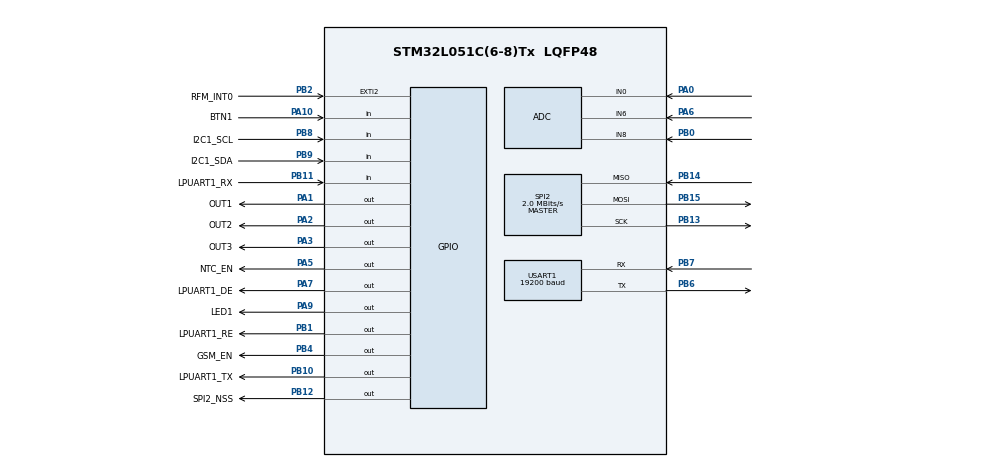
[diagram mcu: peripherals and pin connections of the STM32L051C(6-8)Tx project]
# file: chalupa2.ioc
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ADC.EOCSelection=ADC_EOC_SEQ_CONV
ADC.Overrun=ADC_OVR_DATA_OVERWRITTEN
ADC.OversamplingMode=ENABLE
ADC.Ratio=ADC_OVERSAMPLING_RATIO_16
ADC.RightBitShift=ADC_RIGHTBITSHIFT_4
ADC.SamplingTime=ADC_SAMPLETIME_160CYCLES_5
IWDG.Prescaler=IWDG_PRESCALER_64
Mcu.Family=STM32L0
Mcu.Name=STM32L051C(6-8)Tx
Mcu.Package=LQFP48
NVIC.EXTI2_3_IRQn=true\:0\:0\:false\:false\:true\:true\:true\:true
PA0.Mode=IN0
PA0.Signal=ADC_IN0
PA1.GPIO_Label=OUT1
PA1.Signal=GPIO_Output
PA10.GPIO_Label=BTN1
PA10.GPIO_PuPd=GPIO_PULLUP
PA10.Signal=GPIO_Input
PA13.Mode=Serial_Wire
PA13.Signal=SYS_SWDIO
PA14.Mode=Serial_Wire
PA14.Signal=SYS_SWCLK
PA2.GPIO_Label=OUT2
PA2.Signal=GPIO_Output
PA3.GPIO_Label=OUT3
PA3.Signal=GPIO_Output
PA5.GPIO_Label=NTC_EN
PA5.Signal=GPIO_Output
PA6.Mode=IN6
PA6.Signal=ADC_IN6
PA7.GPIO_Label=LPUART1_DE
PA7.Signal=GPIO_Output
PA9.GPIO_Label=LED1
PA9.Signal=GPIO_Output
PB0.Mode=IN8
PB0.Signal=ADC_IN8
PB1.GPIO_Label=LPUART1_RE
PB1.PinState=GPIO_PIN_SET
PB1.Signal=GPIO_Output
PB10.GPIO_Label=LPUART1_TX
PB10.Signal=GPIO_Output
PB11.GPIO_Label=LPUART1_RX
PB11.GPIO_PuPd=GPIO_PULLUP
PB11.Signal=GPIO_Input
PB12.GPIO_Label=SPI2_NSS
PB12.GPIO_Speed=GPIO_SPEED_FREQ_VERY_HIGH
PB12.PinState=GPIO_PIN_SET
PB12.Signal=GPIO_Output
PB13.GPIO_PuPd=GPIO_PULLDOWN
PB13.Mode=Full_Duplex_Master
PB13.Signal=SPI2_SCK
PB14.GPIO_PuPd=GPIO_PULLDOWN
PB14.Mode=Full_Duplex_Master
PB14.Signal=SPI2_MISO
PB15.GPIO_PuPd=GPIO_PULLDOWN
PB15.Mode=Full_Duplex_Master
PB15.Signal=SPI2_MOSI
PB2.GPIO_Label=RFM_INT0
PB2.GPIO_ModeDefaultEXTI=GPIO_MODE_IT_FALLING
PB2.GPIO_PuPd=GPIO_PULLUP
PB2.Signal=GPXTI2
PB4.GPIO_Label=GSM_EN
PB4.Signal=GPIO_Output
PB6.Mode=Asynchronous
PB6.Signal=USART1_TX
PB7.GPIO_PuPd=GPIO_PULLDOWN
PB7.Mode=Asynchronous
PB7.Signal=USART1_RX
PB8.GPIO_Label=I2C1_SCL
PB8.Signal=GPIO_Input
PB9.GPIO_Label=I2C1_SDA
PB9.Signal=GPIO_Input
PH0-OSC_IN.Mode=HSE-External-Oscillator
PH0-OSC_IN.Signal=RCC_OSC_IN
PH1-OSC_OUT.Mode=HSE-External-Oscillator
PH1-OSC_OUT.Signal=RCC_OSC_OUT
ProjectManager.HeapSize=0x0
ProjectManager.StackSize=0x400
ProjectManager.TargetToolchain=STM32CubeIDE
RCC.AHBFreq_Value=8000000
RCC.APB1Freq_Value=8000000
RCC.APB1TimFreq_Value=8000000
RCC.APB2Freq_Value=8000000
RCC.APB2TimFreq_Value=8000000
RCC.HCLKFreq_Value=8000000
RCC.HSE_VALUE=8000000
RCC.HSI16_VALUE=16000000
RCC.HSI_VALUE=16000000
RCC.LSE_VALUE=32768
RCC.MSI_VALUE=2097000
RCC.PWR_Regulator_Voltage_Scale=PWR_REGULATOR_VOLTAGE_SCALE2
RCC.SYSCLKFreq_VALUE=8000000
RCC.SYSCLKSource=RCC_SYSCLKSOURCE_HSE
RCC.VCOOutputFreq_Value=48000000
RCC.VDD_VALUE=3
SPI2.BaudRatePrescaler=SPI_BAUDRATEPRESCALER_4
SPI2.CalculateBaudRate=2.0 MBits/s
SPI2.DataSize=SPI_DATASIZE_16BIT
SPI2.Direction=SPI_DIRECTION_2LINES
SPI2.Mode=SPI_MODE_MASTER
SPI2.VirtualType=VM_MASTER
USART1.BaudRate=19200
USART1.VirtualMode-Asynchronous=VM_ASYNC
VP_IWDG_VS_IWDG.Mode=IWDG_Activate
board=custom

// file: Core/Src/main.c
/* USER CODE BEGIN Header */
/**
  ******************************************************************************
  * @file           : main.c
  * @brief          : Main program body
  ******************************************************************************
  * @attention
  *
  * Copyright (c) 2023 STMicroelectronics.
  * All rights reserved.
  *
  * This software is licensed under terms that can be found in the LICENSE file
  * in the root directory of this software component.
  * If no LICENSE file comes with this software, it is provided AS-IS.
  *
  ******************************************************************************
  */
/* USER CODE END Header */
#include "main.h"

void SystemClock_Config(void);
static void MX_GPIO_Init(void);
static void MX_ADC_Init(void);
static void MX_USART1_UART_Init(void);
static void MX_SPI2_Init(void);
static void MX_IWDG_Init(void);
/* USER CODE BEGIN PFP */

extern void main2(void);

/* USER CODE END PFP */

int main(void)
{

  /* MCU Configuration--------------------------------------------------------*/

  /* Reset of all peripherals, Initializes the Flash interface and the Systick. */
  LL_APB2_GRP1_EnableClock(LL_APB2_GRP1_PERIPH_SYSCFG);
  LL_APB1_GRP1_EnableClock(LL_APB1_GRP1_PERIPH_PWR);

  /* SysTick_IRQn interrupt configuration */
  NVIC_SetPriority(SysTick_IRQn, 3);

  /* Configure the system clock */
  SystemClock_Config();

  /* Initialize all configured peripherals */
  MX_GPIO_Init();
  MX_ADC_Init();
  MX_USART1_UART_Init();
  MX_SPI2_Init();
  MX_IWDG_Init();
  /* USER CODE BEGIN 2 */

  main2();

  /* USER CODE END 2 */

  /* Infinite loop */
  while (1)
  {

  }
}

void SystemClock_Config(void)
{
  LL_FLASH_SetLatency(LL_FLASH_LATENCY_0);
  while(LL_FLASH_GetLatency()!= LL_FLASH_LATENCY_0)
  {
  }
  LL_PWR_SetRegulVoltageScaling(LL_PWR_REGU_VOLTAGE_SCALE2);
  LL_RCC_HSE_Enable();

   /* Wait till HSE is ready */
  while(LL_RCC_HSE_IsReady() != 1)
  {

  }
  LL_RCC_LSI_Enable();

   /* Wait till LSI is ready */
  while(LL_RCC_LSI_IsReady() != 1)
  {

  }
  LL_RCC_SetAHBPrescaler(LL_RCC_SYSCLK_DIV_1);
  LL_RCC_SetAPB1Prescaler(LL_RCC_APB1_DIV_1);
  LL_RCC_SetAPB2Prescaler(LL_RCC_APB2_DIV_1);
  LL_RCC_SetSysClkSource(LL_RCC_SYS_CLKSOURCE_HSE);

   /* Wait till System clock is ready */
  while(LL_RCC_GetSysClkSource() != LL_RCC_SYS_CLKSOURCE_STATUS_HSE)
  {

  }

  LL_Init1msTick(8000000);

  LL_SetSystemCoreClock(8000000);
  LL_RCC_SetUSARTClockSource(LL_RCC_USART1_CLKSOURCE_PCLK2);
}

static void MX_ADC_Init(void)
{

  LL_ADC_REG_InitTypeDef ADC_REG_InitStruct = {0};
  LL_ADC_InitTypeDef ADC_InitStruct = {0};

  LL_GPIO_InitTypeDef GPIO_InitStruct = {0};

  /* Peripheral clock enable */
  LL_APB2_GRP1_EnableClock(LL_APB2_GRP1_PERIPH_ADC1);

  LL_IOP_GRP1_EnableClock(LL_IOP_GRP1_PERIPH_GPIOA);
  LL_IOP_GRP1_EnableClock(LL_IOP_GRP1_PERIPH_GPIOB);
  /**ADC GPIO Configuration
  PA0   ------> ADC_IN0
  PA6   ------> ADC_IN6
  PB0   ------> ADC_IN8
  */
  GPIO_InitStruct.Pin = LL_GPIO_PIN_0;
  GPIO_InitStruct.Mode = LL_GPIO_MODE_ANALOG;
  GPIO_InitStruct.Pull = LL_GPIO_PULL_NO;
  LL_GPIO_Init(GPIOA, &GPIO_InitStruct);

  GPIO_InitStruct.Pin = LL_GPIO_PIN_6;
  GPIO_InitStruct.Mode = LL_GPIO_MODE_ANALOG;
  GPIO_InitStruct.Pull = LL_GPIO_PULL_NO;
  LL_GPIO_Init(GPIOA, &GPIO_InitStruct);

  GPIO_InitStruct.Pin = LL_GPIO_PIN_0;
  GPIO_InitStruct.Mode = LL_GPIO_MODE_ANALOG;
  GPIO_InitStruct.Pull = LL_GPIO_PULL_NO;
  LL_GPIO_Init(GPIOB, &GPIO_InitStruct);

  /** Configure Regular Channel
  */
  LL_ADC_REG_SetSequencerChAdd(ADC1, LL_ADC_CHANNEL_0);

  /** Configure Regular Channel
  */
  LL_ADC_REG_SetSequencerChAdd(ADC1, LL_ADC_CHANNEL_6);

  /** Configure Regular Channel
  */
  LL_ADC_REG_SetSequencerChAdd(ADC1, LL_ADC_CHANNEL_8);

  /** Common config
  */
  ADC_REG_InitStruct.TriggerSource = LL_ADC_REG_TRIG_SOFTWARE;
  ADC_REG_InitStruct.SequencerDiscont = LL_ADC_REG_SEQ_DISCONT_DISABLE;
  ADC_REG_InitStruct.ContinuousMode = LL_ADC_REG_CONV_SINGLE;
  ADC_REG_InitStruct.DMATransfer = LL_ADC_REG_DMA_TRANSFER_NONE;
  ADC_REG_InitStruct.Overrun = LL_ADC_REG_OVR_DATA_OVERWRITTEN;
  LL_ADC_REG_Init(ADC1, &ADC_REG_InitStruct);
  LL_ADC_SetSamplingTimeCommonChannels(ADC1, LL_ADC_SAMPLINGTIME_160CYCLES_5);
  LL_ADC_SetOverSamplingScope(ADC1, LL_ADC_OVS_GRP_REGULAR_CONTINUED);
  LL_ADC_ConfigOverSamplingRatioShift(ADC1, LL_ADC_OVS_RATIO_16, LL_ADC_OVS_SHIFT_RIGHT_4);
  LL_ADC_SetOverSamplingDiscont(ADC1, LL_ADC_OVS_REG_CONT);
  LL_ADC_REG_SetSequencerScanDirection(ADC1, LL_ADC_REG_SEQ_SCAN_DIR_FORWARD);
  LL_ADC_SetCommonFrequencyMode(__LL_ADC_COMMON_INSTANCE(ADC1), LL_ADC_CLOCK_FREQ_MODE_HIGH);
  LL_ADC_DisableIT_EOC(ADC1);
  LL_ADC_DisableIT_EOS(ADC1);
  ADC_InitStruct.Clock = LL_ADC_CLOCK_SYNC_PCLK_DIV1;
  ADC_InitStruct.Resolution = LL_ADC_RESOLUTION_12B;
  ADC_InitStruct.DataAlignment = LL_ADC_DATA_ALIGN_RIGHT;
  ADC_InitStruct.LowPowerMode = LL_ADC_LP_MODE_NONE;
  LL_ADC_Init(ADC1, &ADC_InitStruct);

  /* Enable ADC internal voltage regulator */
  LL_ADC_EnableInternalRegulator(ADC1);
  /* Delay for ADC internal voltage regulator stabilization. */
  /* Compute number of CPU cycles to wait for, from delay in us. */
  /* Note: Variable divided by 2 to compensate partially */
  /* CPU processing cycles (depends on compilation optimization). */
  /* Note: If system core clock frequency is below 200kHz, wait time */
  /* is only a few CPU processing cycles. */
  uint32_t wait_loop_index;
  wait_loop_index = ((LL_ADC_DELAY_INTERNAL_REGUL_STAB_US * (SystemCoreClock / (100000 * 2))) / 10);
  while(wait_loop_index != 0)
  {
    wait_loop_index--;
  }

}

static void MX_IWDG_Init(void)
{

  LL_IWDG_Enable(IWDG);
  LL_IWDG_EnableWriteAccess(IWDG);
  LL_IWDG_SetPrescaler(IWDG, LL_IWDG_PRESCALER_64);
  LL_IWDG_SetReloadCounter(IWDG, 4095);
  while (LL_IWDG_IsReady(IWDG) != 1)
  {
  }

  LL_IWDG_ReloadCounter(IWDG);

}

static void MX_SPI2_Init(void)
{

  LL_SPI_InitTypeDef SPI_InitStruct = {0};

  LL_GPIO_InitTypeDef GPIO_InitStruct = {0};

  /* Peripheral clock enable */
  LL_APB1_GRP1_EnableClock(LL_APB1_GRP1_PERIPH_SPI2);

  LL_IOP_GRP1_EnableClock(LL_IOP_GRP1_PERIPH_GPIOB);
  /**SPI2 GPIO Configuration
  PB13   ------> SPI2_SCK
  PB14   ------> SPI2_MISO
  PB15   ------> SPI2_MOSI
  */
  GPIO_InitStruct.Pin = LL_GPIO_PIN_13;
  GPIO_InitStruct.Mode = LL_GPIO_MODE_ALTERNATE;
  GPIO_InitStruct.Speed = LL_GPIO_SPEED_FREQ_VERY_HIGH;
  GPIO_InitStruct.OutputType = LL_GPIO_OUTPUT_PUSHPULL;
  GPIO_InitStruct.Pull = LL_GPIO_PULL_DOWN;
  GPIO_InitStruct.Alternate = LL_GPIO_AF_0;
  LL_GPIO_Init(GPIOB, &GPIO_InitStruct);

  GPIO_InitStruct.Pin = LL_GPIO_PIN_14;
  GPIO_InitStruct.Mode = LL_GPIO_MODE_ALTERNATE;
  GPIO_InitStruct.Speed = LL_GPIO_SPEED_FREQ_VERY_HIGH;
  GPIO_InitStruct.OutputType = LL_GPIO_OUTPUT_PUSHPULL;
  GPIO_InitStruct.Pull = LL_GPIO_PULL_DOWN;
  GPIO_InitStruct.Alternate = LL_GPIO_AF_0;
  LL_GPIO_Init(GPIOB, &GPIO_InitStruct);

  GPIO_InitStruct.Pin = LL_GPIO_PIN_15;
  GPIO_InitStruct.Mode = LL_GPIO_MODE_ALTERNATE;
  GPIO_InitStruct.Speed = LL_GPIO_SPEED_FREQ_VERY_HIGH;
  GPIO_InitStruct.OutputType = LL_GPIO_OUTPUT_PUSHPULL;
  GPIO_InitStruct.Pull = LL_GPIO_PULL_DOWN;
  GPIO_InitStruct.Alternate = LL_GPIO_AF_0;
  LL_GPIO_Init(GPIOB, &GPIO_InitStruct);

  /* SPI2 parameter configuration*/
  SPI_InitStruct.TransferDirection = LL_SPI_FULL_DUPLEX;
  SPI_InitStruct.Mode = LL_SPI_MODE_MASTER;
  SPI_InitStruct.DataWidth = LL_SPI_DATAWIDTH_16BIT;
  SPI_InitStruct.ClockPolarity = LL_SPI_POLARITY_LOW;
  SPI_InitStruct.ClockPhase = LL_SPI_PHASE_1EDGE;
  SPI_InitStruct.NSS = LL_SPI_NSS_SOFT;
  SPI_InitStruct.BaudRate = LL_SPI_BAUDRATEPRESCALER_DIV4;
  SPI_InitStruct.BitOrder = LL_SPI_MSB_FIRST;
  SPI_InitStruct.CRCCalculation = LL_SPI_CRCCALCULATION_DISABLE;
  SPI_InitStruct.CRCPoly = 7;
  LL_SPI_Init(SPI2, &SPI_InitStruct);
  LL_SPI_SetStandard(SPI2, LL_SPI_PROTOCOL_MOTOROLA);

}

static void MX_USART1_UART_Init(void)
{

  LL_USART_InitTypeDef USART_InitStruct = {0};

  LL_GPIO_InitTypeDef GPIO_InitStruct = {0};

  /* Peripheral clock enable */
  LL_APB2_GRP1_EnableClock(LL_APB2_GRP1_PERIPH_USART1);

  LL_IOP_GRP1_EnableClock(LL_IOP_GRP1_PERIPH_GPIOB);
  /**USART1 GPIO Configuration
  PB6   ------> USART1_TX
  PB7   ------> USART1_RX
  */
  GPIO_InitStruct.Pin = LL_GPIO_PIN_6;
  GPIO_InitStruct.Mode = LL_GPIO_MODE_ALTERNATE;
  GPIO_InitStruct.Speed = LL_GPIO_SPEED_FREQ_VERY_HIGH;
  GPIO_InitStruct.OutputType = LL_GPIO_OUTPUT_PUSHPULL;
  GPIO_InitStruct.Pull = LL_GPIO_PULL_NO;
  GPIO_InitStruct.Alternate = LL_GPIO_AF_0;
  LL_GPIO_Init(GPIOB, &GPIO_InitStruct);

  GPIO_InitStruct.Pin = LL_GPIO_PIN_7;
  GPIO_InitStruct.Mode = LL_GPIO_MODE_ALTERNATE;
  GPIO_InitStruct.Speed = LL_GPIO_SPEED_FREQ_VERY_HIGH;
  GPIO_InitStruct.OutputType = LL_GPIO_OUTPUT_PUSHPULL;
  GPIO_InitStruct.Pull = LL_GPIO_PULL_DOWN;
  GPIO_InitStruct.Alternate = LL_GPIO_AF_0;
  LL_GPIO_Init(GPIOB, &GPIO_InitStruct);

  USART_InitStruct.BaudRate = 19200;
  USART_InitStruct.DataWidth = LL_USART_DATAWIDTH_8B;
  USART_InitStruct.StopBits = LL_USART_STOPBITS_1;
  USART_InitStruct.Parity = LL_USART_PARITY_NONE;
  USART_InitStruct.TransferDirection = LL_USART_DIRECTION_TX_RX;
  USART_InitStruct.HardwareFlowControl = LL_USART_HWCONTROL_NONE;
  USART_InitStruct.OverSampling = LL_USART_OVERSAMPLING_16;
  LL_USART_Init(USART1, &USART_InitStruct);
  LL_USART_ConfigAsyncMode(USART1);
  LL_USART_Enable(USART1);

}

static void MX_GPIO_Init(void)
{
  LL_EXTI_InitTypeDef EXTI_InitStruct = {0};
  LL_GPIO_InitTypeDef GPIO_InitStruct = {0};

  /* GPIO Ports Clock Enable */
  LL_IOP_GRP1_EnableClock(LL_IOP_GRP1_PERIPH_GPIOC);
  LL_IOP_GRP1_EnableClock(LL_IOP_GRP1_PERIPH_GPIOH);
  LL_IOP_GRP1_EnableClock(LL_IOP_GRP1_PERIPH_GPIOA);
  LL_IOP_GRP1_EnableClock(LL_IOP_GRP1_PERIPH_GPIOB);

  /**/
  LL_GPIO_ResetOutputPin(OUT1_GPIO_Port, OUT1_Pin);

  /**/
  LL_GPIO_ResetOutputPin(OUT2_GPIO_Port, OUT2_Pin);

  /**/
  LL_GPIO_ResetOutputPin(OUT3_GPIO_Port, OUT3_Pin);

  /**/
  LL_GPIO_ResetOutputPin(NTC_EN_GPIO_Port, NTC_EN_Pin);

  /**/
  LL_GPIO_ResetOutputPin(LPUART1_DE_GPIO_Port, LPUART1_DE_Pin);

  /**/
  LL_GPIO_ResetOutputPin(LPUART1_TX_GPIO_Port, LPUART1_TX_Pin);

  /**/
  LL_GPIO_ResetOutputPin(LED1_GPIO_Port, LED1_Pin);

  /**/
  LL_GPIO_ResetOutputPin(GSM_EN_GPIO_Port, GSM_EN_Pin);

  /**/
  LL_GPIO_SetOutputPin(LPUART1_RE_GPIO_Port, LPUART1_RE_Pin);

  /**/
  LL_GPIO_SetOutputPin(SPI2_NSS_GPIO_Port, SPI2_NSS_Pin);

  /**/
  GPIO_InitStruct.Pin = LL_GPIO_PIN_13;
  GPIO_InitStruct.Mode = LL_GPIO_MODE_ANALOG;
  GPIO_InitStruct.Pull = LL_GPIO_PULL_NO;
  LL_GPIO_Init(GPIOC, &GPIO_InitStruct);

  /**/
  GPIO_InitStruct.Pin = LL_GPIO_PIN_14;
  GPIO_InitStruct.Mode = LL_GPIO_MODE_ANALOG;
  GPIO_InitStruct.Pull = LL_GPIO_PULL_NO;
  LL_GPIO_Init(GPIOC, &GPIO_InitStruct);

  /**/
  GPIO_InitStruct.Pin = LL_GPIO_PIN_15;
  GPIO_InitStruct.Mode = LL_GPIO_MODE_ANALOG;
  GPIO_InitStruct.Pull = LL_GPIO_PULL_NO;
  LL_GPIO_Init(GPIOC, &GPIO_InitStruct);

  /**/
  GPIO_InitStruct.Pin = OUT1_Pin;
  GPIO_InitStruct.Mode = LL_GPIO_MODE_OUTPUT;
  GPIO_InitStruct.Speed = LL_GPIO_SPEED_FREQ_LOW;
  GPIO_InitStruct.OutputType = LL_GPIO_OUTPUT_PUSHPULL;
  GPIO_InitStruct.Pull = LL_GPIO_PULL_NO;
  LL_GPIO_Init(OUT1_GPIO_Port, &GPIO_InitStruct);

  /**/
  GPIO_InitStruct.Pin = OUT2_Pin;
  GPIO_InitStruct.Mode = LL_GPIO_MODE_OUTPUT;
  GPIO_InitStruct.Speed = LL_GPIO_SPEED_FREQ_LOW;
  GPIO_InitStruct.OutputType = LL_GPIO_OUTPUT_PUSHPULL;
  GPIO_InitStruct.Pull = LL_GPIO_PULL_NO;
  LL_GPIO_Init(OUT2_GPIO_Port, &GPIO_InitStruct);

  /**/
  GPIO_InitStruct.Pin = OUT3_Pin;
  GPIO_InitStruct.Mode = LL_GPIO_MODE_OUTPUT;
  GPIO_InitStruct.Speed = LL_GPIO_SPEED_FREQ_LOW;
  GPIO_InitStruct.OutputType = LL_GPIO_OUTPUT_PUSHPULL;
  GPIO_InitStruct.Pull = LL_GPIO_PULL_NO;
  LL_GPIO_Init(OUT3_GPIO_Port, &GPIO_InitStruct);

  /**/
  GPIO_InitStruct.Pin = LL_GPIO_PIN_4;
  GPIO_InitStruct.Mode = LL_GPIO_MODE_ANALOG;
  GPIO_InitStruct.Pull = LL_GPIO_PULL_NO;
  LL_GPIO_Init(GPIOA, &GPIO_InitStruct);

  /**/
  GPIO_InitStruct.Pin = NTC_EN_Pin;
  GPIO_InitStruct.Mode = LL_GPIO_MODE_OUTPUT;
  GPIO_InitStruct.Speed = LL_GPIO_SPEED_FREQ_LOW;
  GPIO_InitStruct.OutputType = LL_GPIO_OUTPUT_PUSHPULL;
  GPIO_InitStruct.Pull = LL_GPIO_PULL_NO;
  LL_GPIO_Init(NTC_EN_GPIO_Port, &GPIO_InitStruct);

  /**/
  GPIO_InitStruct.Pin = LPUART1_DE_Pin;
  GPIO_InitStruct.Mode = LL_GPIO_MODE_OUTPUT;
  GPIO_InitStruct.Speed = LL_GPIO_SPEED_FREQ_LOW;
  GPIO_InitStruct.OutputType = LL_GPIO_OUTPUT_PUSHPULL;
  GPIO_InitStruct.Pull = LL_GPIO_PULL_NO;
  LL_GPIO_Init(LPUART1_DE_GPIO_Port, &GPIO_InitStruct);

  /**/
  GPIO_InitStruct.Pin = LPUART1_RE_Pin;
  GPIO_InitStruct.Mode = LL_GPIO_MODE_OUTPUT;
  GPIO_InitStruct.Speed = LL_GPIO_SPEED_FREQ_LOW;
  GPIO_InitStruct.OutputType = LL_GPIO_OUTPUT_PUSHPULL;
  GPIO_InitStruct.Pull = LL_GPIO_PULL_NO;
  LL_GPIO_Init(LPUART1_RE_GPIO_Port, &GPIO_InitStruct);

  /**/
  GPIO_InitStruct.Pin = LPUART1_TX_Pin;
  GPIO_InitStruct.Mode = LL_GPIO_MODE_OUTPUT;
  GPIO_InitStruct.Speed = LL_GPIO_SPEED_FREQ_LOW;
  GPIO_InitStruct.OutputType = LL_GPIO_OUTPUT_PUSHPULL;
  GPIO_InitStruct.Pull = LL_GPIO_PULL_NO;
  LL_GPIO_Init(LPUART1_TX_GPIO_Port, &GPIO_InitStruct);

  /**/
  GPIO_InitStruct.Pin = LPUART1_RX_Pin;
  GPIO_InitStruct.Mode = LL_GPIO_MODE_INPUT;
  GPIO_InitStruct.Pull = LL_GPIO_PULL_UP;
  LL_GPIO_Init(LPUART1_RX_GPIO_Port, &GPIO_InitStruct);

  /**/
  GPIO_InitStruct.Pin = SPI2_NSS_Pin;
  GPIO_InitStruct.Mode = LL_GPIO_MODE_OUTPUT;
  GPIO_InitStruct.Speed = LL_GPIO_SPEED_FREQ_VERY_HIGH;
  GPIO_InitStruct.OutputType = LL_GPIO_OUTPUT_PUSHPULL;
  GPIO_InitStruct.Pull = LL_GPIO_PULL_NO;
  LL_GPIO_Init(SPI2_NSS_GPIO_Port, &GPIO_InitStruct);

  /**/
  GPIO_InitStruct.Pin = LL_GPIO_PIN_8;
  GPIO_InitStruct.Mode = LL_GPIO_MODE_ANALOG;
  GPIO_InitStruct.Pull = LL_GPIO_PULL_NO;
  LL_GPIO_Init(GPIOA, &GPIO_InitStruct);

  /**/
  GPIO_InitStruct.Pin = LED1_Pin;
  GPIO_InitStruct.Mode = LL_GPIO_MODE_OUTPUT;
  GPIO_InitStruct.Speed = LL_GPIO_SPEED_FREQ_LOW;
  GPIO_InitStruct.OutputType = LL_GPIO_OUTPUT_PUSHPULL;
  GPIO_InitStruct.Pull = LL_GPIO_PULL_NO;
  LL_GPIO_Init(LED1_GPIO_Port, &GPIO_InitStruct);

  /**/
  GPIO_InitStruct.Pin = BTN1_Pin;
  GPIO_InitStruct.Mode = LL_GPIO_MODE_INPUT;
  GPIO_InitStruct.Pull = LL_GPIO_PULL_UP;
  LL_GPIO_Init(BTN1_GPIO_Port, &GPIO_InitStruct);

  /**/
  GPIO_InitStruct.Pin = LL_GPIO_PIN_11;
  GPIO_InitStruct.Mode = LL_GPIO_MODE_ANALOG;
  GPIO_InitStruct.Pull = LL_GPIO_PULL_NO;
  LL_GPIO_Init(GPIOA, &GPIO_InitStruct);

  /**/
  GPIO_InitStruct.Pin = LL_GPIO_PIN_12;
  GPIO_InitStruct.Mode = LL_GPIO_MODE_ANALOG;
  GPIO_InitStruct.Pull = LL_GPIO_PULL_NO;
  LL_GPIO_Init(GPIOA, &GPIO_InitStruct);

  /**/
  GPIO_InitStruct.Pin = LL_GPIO_PIN_15;
  GPIO_InitStruct.Mode = LL_GPIO_MODE_ANALOG;
  GPIO_InitStruct.Pull = LL_GPIO_PULL_NO;
  LL_GPIO_Init(GPIOA, &GPIO_InitStruct);

  /**/
  GPIO_InitStruct.Pin = LL_GPIO_PIN_3;
  GPIO_InitStruct.Mode = LL_GPIO_MODE_ANALOG;
  GPIO_InitStruct.Pull = LL_GPIO_PULL_NO;
  LL_GPIO_Init(GPIOB, &GPIO_InitStruct);

  /**/
  GPIO_InitStruct.Pin = GSM_EN_Pin;
  GPIO_InitStruct.Mode = LL_GPIO_MODE_OUTPUT;
  GPIO_InitStruct.Speed = LL_GPIO_SPEED_FREQ_LOW;
  GPIO_InitStruct.OutputType = LL_GPIO_OUTPUT_PUSHPULL;
  GPIO_InitStruct.Pull = LL_GPIO_PULL_NO;
  LL_GPIO_Init(GSM_EN_GPIO_Port, &GPIO_InitStruct);

  /**/
  GPIO_InitStruct.Pin = LL_GPIO_PIN_5;
  GPIO_InitStruct.Mode = LL_GPIO_MODE_ANALOG;
  GPIO_InitStruct.Pull = LL_GPIO_PULL_NO;
  LL_GPIO_Init(GPIOB, &GPIO_InitStruct);

  /**/
  GPIO_InitStruct.Pin = I2C1_SCL_Pin;
  GPIO_InitStruct.Mode = LL_GPIO_MODE_INPUT;
  GPIO_InitStruct.Pull = LL_GPIO_PULL_NO;
  LL_GPIO_Init(I2C1_SCL_GPIO_Port, &GPIO_InitStruct);

  /**/
  GPIO_InitStruct.Pin = I2C1_SDA_Pin;
  GPIO_InitStruct.Mode = LL_GPIO_MODE_INPUT;
  GPIO_InitStruct.Pull = LL_GPIO_PULL_NO;
  LL_GPIO_Init(I2C1_SDA_GPIO_Port, &GPIO_InitStruct);

  /**/
  LL_SYSCFG_SetEXTISource(LL_SYSCFG_EXTI_PORTB, LL_SYSCFG_EXTI_LINE2);

  /**/
  LL_GPIO_SetPinPull(RFM_INT0_GPIO_Port, RFM_INT0_Pin, LL_GPIO_PULL_UP);

  /**/
  LL_GPIO_SetPinMode(RFM_INT0_GPIO_Port, RFM_INT0_Pin, LL_GPIO_MODE_INPUT);

  /**/
  EXTI_InitStruct.Line_0_31 = LL_EXTI_LINE_2;
  EXTI_InitStruct.LineCommand = ENABLE;
  EXTI_InitStruct.Mode = LL_EXTI_MODE_IT;
  EXTI_InitStruct.Trigger = LL_EXTI_TRIGGER_FALLING;
  LL_EXTI_Init(&EXTI_InitStruct);

  /* EXTI interrupt init*/
  NVIC_SetPriority(EXTI2_3_IRQn, 0);
  NVIC_EnableIRQ(EXTI2_3_IRQn);

}

void Error_Handler(void)
{
  __disable_irq();
  while (1)
  {
  }
}
